# FM33FG0XXA register map
File version: 1.0
CPU: SC000 r1p0, little endian, MPU, no FPU, 3 interrupt priority bits
Registers are 32-bit, read-only, reset 0x0 unless marked. A register's access mark holds for its fields unless they carry their own. Offsets are from the block's base; [hi:lo] are bit positions; {n}, {i} and the like mark numbered series; 'fields as' and 'values as' point back to an identical list.

## CANFD0 — CANFD0 module information
Base 0x40020000
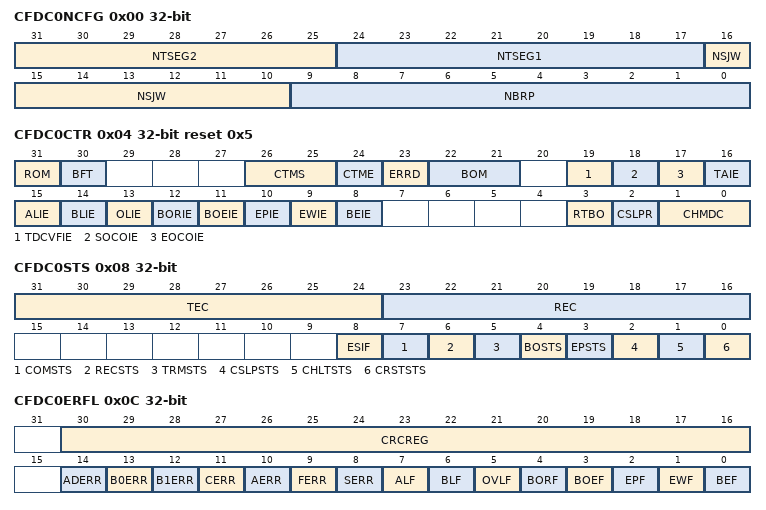
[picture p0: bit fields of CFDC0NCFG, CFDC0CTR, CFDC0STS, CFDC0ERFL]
0x00 CFDC0NCFG rw
  [31:25] NTSEG2 — NTSEG2 field description
  [24:17] NTSEG1 — NTSEG1 field description
  [16:10] NSJW — NSJW field description
  [9:0] NBRP — NBRP field description
0x04 CFDC0CTR rw reset 0x5
  [31] ROM — ROM field description
  [30] BFT — BFT field description
  [26:25] CTMS — CTMS field description
  [24] CTME — CTME field description
  [23] ERRD — ERRD field description
  [22:21] BOM — BOM field description
  [19] TDCVFIE — TDCVFIE field description
  [18] SOCOIE — SOCOIE field description
  [17] EOCOIE — EOCOIE field description
  [16] TAIE — TAIE field description
  [15] ALIE — ALIE field description
  [14] BLIE — BLIE field description
  [13] OLIE — OLIE field description
  [12] BORIE — BORIE field description
  [11] BOEIE — BOEIE field description
  [10] EPIE — EPIE field description
  [9] EWIE — EWIE field description
  [8] BEIE — BEIE field description
  [3] RTBO — RTBO field description
  [2] CSLPR — CSLPR field description
  [1:0] CHMDC — CHMDC field description
0x08 CFDC0STS access per field
  [31:24] TEC ro — TEC field description
  [23:16] REC ro — REC field description
  [8] ESIF rw — ESIF field description
  [7] COMSTS ro — COMSTS field description
  [6] RECSTS ro — RECSTS field description
  [5] TRMSTS ro — TRMSTS field description
  [4] BOSTS ro — BOSTS field description
  [3] EPSTS ro — EPSTS field description
  [2] CSLPSTS ro — CSLPSTS field description
  [1] CHLTSTS ro — CHLTSTS field description
  [0] CRSTSTS ro — CRSTSTS field description
0x0C CFDC0ERFL access per field
  [30:16] CRCREG ro — CRCREG field description
  [14] ADERR rw — ADERR field description
  [13] B0ERR rw — B0ERR field description
  [12] B1ERR rw — B1ERR field description
  [11] CERR rw — CERR field description
  [10] AERR rw — AERR field description
  [9] FERR rw — FERR field description
  [8] SERR rw — SERR field description
  [7] ALF rw — ALF field description
  [6] BLF rw — BLF field description
  [5] OVLF rw — OVLF field description
  [4] BORF rw — BORF field description
  [3] BOEF rw — BOEF field description
  [2] EPF rw — EPF field description
  [1] EWF rw — EWF field description
  [0] BEF rw — BEF field description
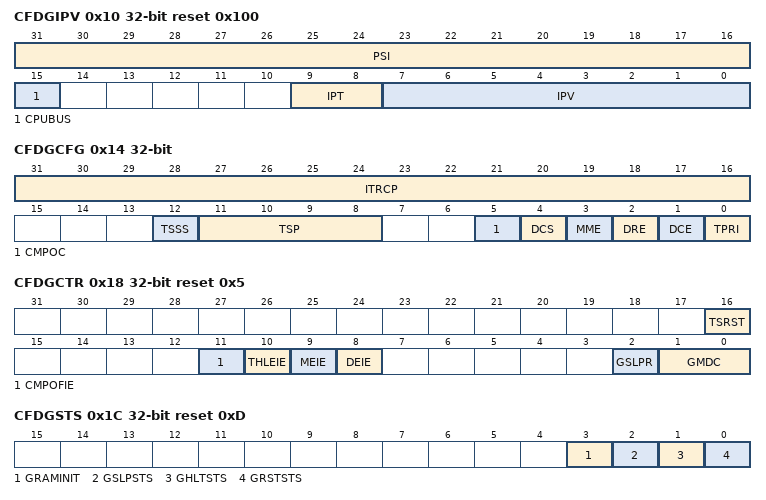
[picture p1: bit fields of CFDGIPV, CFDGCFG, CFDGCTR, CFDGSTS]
0x10 CFDGIPV reset 0x100
  [31:16] PSI — PSI field description
  [15] CPUBUS — CPUBUS field description
  [9:8] IPT — IPT field description
  [7:0] IPV — IPV field description
0x14 CFDGCFG rw
  [31:16] ITRCP — ITRCP field description
  [12] TSSS — TSSS field description
  [11:8] TSP — TSP field description
  [5] CMPOC — CMPOC field description
  [4] DCS — DCS field description
  [3] MME — MME field description
  [2] DRE — DRE field description
  [1] DCE — DCE field description
  [0] TPRI — TPRI field description
0x18 CFDGCTR rw reset 0x5
  [16] TSRST — TSRST field description
  [11] CMPOFIE — CMPOFIE field description
  [10] THLEIE — THLEIE field description
  [9] MEIE — MEIE field description
  [8] DEIE — DEIE field description
  [2] GSLPR — GSLPR field description
  [1:0] GMDC — GMDC field description
0x1C CFDGSTS reset 0xD
  [3] GRAMINIT — GRAMINIT field description
  [2] GSLPSTS — GSLPSTS field description
  [1] GHLTSTS — GHLTSTS field description
  [0] GRSTSTS — GRSTSTS field description
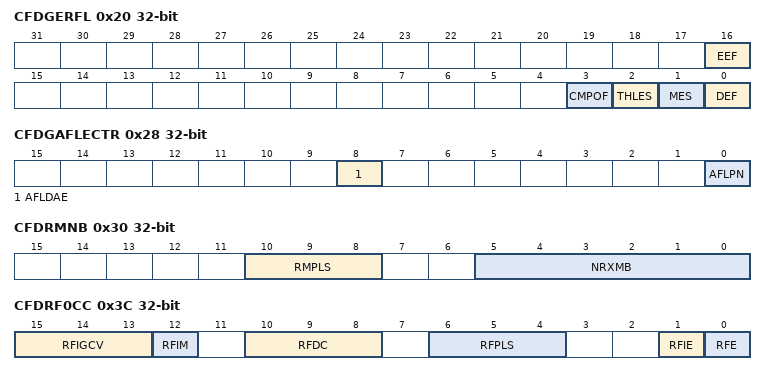
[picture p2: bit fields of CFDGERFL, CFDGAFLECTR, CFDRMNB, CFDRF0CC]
0x20 CFDGERFL access per field
  [16] EEF rw — EEF field description
  [3] CMPOF rw — CMPOF field description
  [2] THLES ro — THLES field description
  [1] MES ro — MES field description
  [0] DEF rw — DEF field description
0x24 CFDGTSC
  [15:0] TS — TS field description
0x28 CFDGAFLECTR rw
  [8] AFLDAE — AFLDAE field description
  [0] AFLPN — AFLPN field description
0x2C CFDGAFLCFG rw
  [21:16] RNC — RNC field description
0x30 CFDRMNB rw
  [10:8] RMPLS — RMPLS field description
  [5:0] NRXMB — NRXMB field description
0x34 CFDRMND rw
  [31:0] RMNSu — RMNSu field description
0x38 CFDRMIEC rw
  [31:0] RMIE — RMIE field description
0x3C CFDRF0CC rw
  [15:13] RFIGCV — RFIGCV field description
  [12] RFIM — RFIM field description
  [10:8] RFDC — RFDC field description
  [6:4] RFPLS — RFPLS field description
  [1] RFIE — RFIE field description
  [0] RFE — RFE field description
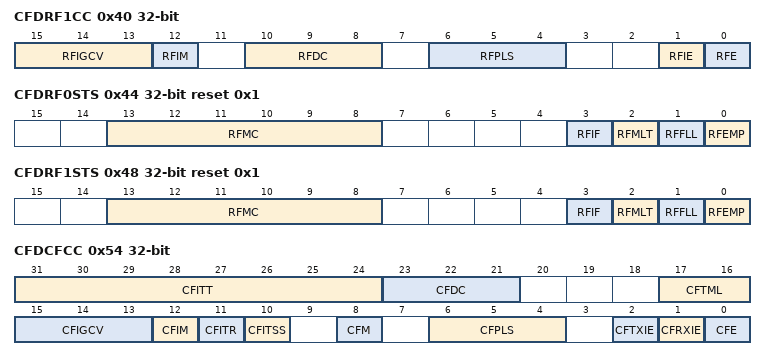
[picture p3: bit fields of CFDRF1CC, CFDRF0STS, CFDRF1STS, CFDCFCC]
0x40 CFDRF1CC rw
  fields as CFDRF0CC
0x44 CFDRF0STS access per field reset 0x1
  [13:8] RFMC ro — RFMC field description
  [3] RFIF rw — RFIF field description
  [2] RFMLT rw — RFMLT field description
  [1] RFFLL ro — RFFLL field description
  [0] RFEMP ro — RFEMP field description
0x48 CFDRF1STS access per field reset 0x1
  fields as CFDRF0STS
0x4C CFDRF0PCTR wo
  [7:0] RFPC — RFPC field description
0x50 CFDRF1PCTR wo
  [7:0] RFPC — RFPC field description
0x54 CFDCFCC rw
  [31:24] CFITT — CFITT field description
  [23:21] CFDC — CFDC field description
  [17:16] CFTML — CFTML field description
  [15:13] CFIGCV — CFIGCV field description
  [12] CFIM — CFIM field description
  [11] CFITR — CFITR field description
  [10] CFITSS — CFITSS field description
  [8] CFM — CFM field description
  [6:4] CFPLS — CFPLS field description
  [2] CFTXIE — CFTXIE field description
  [1] CFRXIE — CFRXIE field description
  [0] CFE — CFE field description
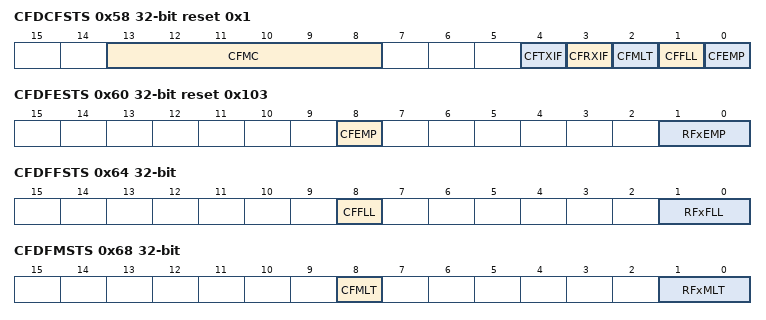
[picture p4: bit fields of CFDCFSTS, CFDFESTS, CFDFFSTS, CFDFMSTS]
0x58 CFDCFSTS access per field reset 0x1
  [13:8] CFMC ro — CFMC field description
  [4] CFTXIF rw — CFTXIF field description
  [3] CFRXIF rw — CFRXIF field description
  [2] CFMLT rw — CFMLT field description
  [1] CFFLL ro — CFFLL field description
  [0] CFEMP ro — CFEMP field description
0x5C CFDCFPCTR wo
  [7:0] CFPC — CFPC field description
0x60 CFDFESTS reset 0x103
  [8] CFEMP — CFEMP field description
  [1:0] RFxEMP — RFxEMP field description
0x64 CFDFFSTS
  [8] CFFLL — CFFLL field description
  [1:0] RFxFLL — RFxFLL field description
0x68 CFDFMSTS
  [8] CFMLT — CFMLT field description
  [1:0] RFxMLT — RFxMLT field description
0x6C CFDRFISTS
  [1:0] RFxIF — RFxIF field description
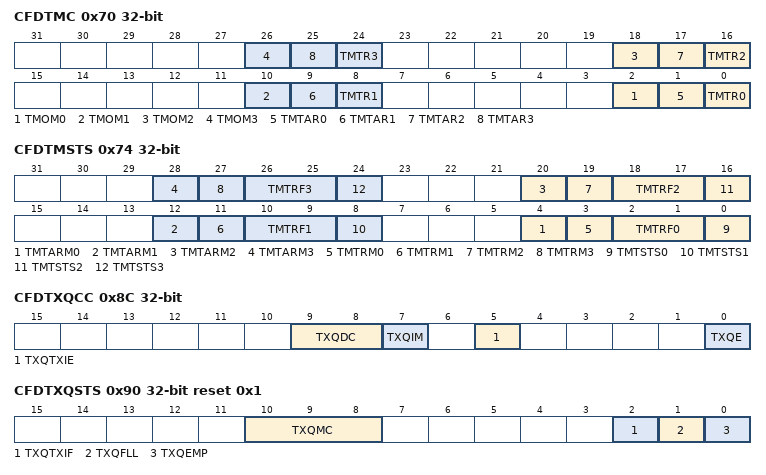
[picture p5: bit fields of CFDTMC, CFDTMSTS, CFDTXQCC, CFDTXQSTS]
0x70 CFDTMC rw
  [8n+2] TMOM{n} (n=0..3) — TMOM{n} field description
  [8n+1] TMTAR{n} (n=0..3) — TMTAR{n} field description
  [8n] TMTR{n} (n=0..3) — TMTR{n} field description
0x74 CFDTMSTS access per field
  [8n+4] TMTARM{n} ro (n=0..3) — TMTARM{n} field description
  [8n+3] TMTRM{n} ro (n=0..3) — TMTRM{n} field description
  [8n+2:8n+1] TMTRF{n} rw (n=0..3) — TMTRF{n} field description
  [8n] TMTSTS{n} ro (n=0..3) — TMTSTS{n} field description
0x78 CFDTMTRSTS
  [3:0] CFDTMTRSTS — CFDTMTRSTS field description
0x7C CFDTMTARSTS
  [3:0] CFDTMTARSTS — CFDTMTARSTS field description
0x80 CFDTMTCSTS
  [3:0] CFDTMTCSTS — CFDTMTCSTS field description
0x84 CFDTMTASTS
  [3:0] CFDTMTASTS — CFDTMTASTS field description
0x88 CFDTMIEC rw
  [3:0] TMIE — TMIE field description
0x8C CFDTXQCC rw
  [9:8] TXQDC — TXQDC field description
  [7] TXQIM — TXQIM field description
  [5] TXQTXIE — TXQTXIE field description
  [0] TXQE — TXQE field description
0x90 CFDTXQSTS access per field reset 0x1
  [10:8] TXQMC ro — TXQMC field description
  [2] TXQTXIF rw — TXQTXIF field description
  [1] TXQFLL ro — TXQFLL field description
  [0] TXQEMP ro — TXQEMP field description
0x94 CFDTXQPCTR wo
  [7:0] TXQPC — TXQPC field description
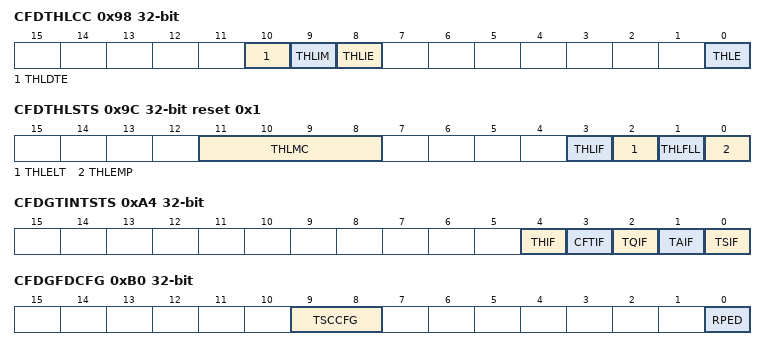
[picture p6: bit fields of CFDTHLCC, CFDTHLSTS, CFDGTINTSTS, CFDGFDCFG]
0x98 CFDTHLCC rw
  [10] THLDTE — THLDTE field description
  [9] THLIM — THLIM field description
  [8] THLIE — THLIE field description
  [0] THLE — THLE field description
0x9C CFDTHLSTS access per field reset 0x1
  [11:8] THLMC ro — THLMC field description
  [3] THLIF rw — THLIF field description
  [2] THLELT rw — THLELT field description
  [1] THLFLL ro — THLFLL field description
  [0] THLEMP ro — THLEMP field description
0xA0 CFDTHLPCTR wo
  [7:0] THLPC — THLPC field description
0xA4 CFDGTINTSTS
  [4] THIF — THIF field description
  [3] CFTIF — CFTIF field description
  [2] TQIF — TQIF field description
  [1] TAIF — TAIF field description
  [0] TSIF — TSIF field description
0xA8 CFDGTSTCFG rw
  [19:16] RTMPS — RTMPS field description
0xAC CFDGTSTCTR rw
  [2] RTME — RTME field description
0xB0 CFDGFDCFG rw
  [9:8] TSCCFG — TSCCFG field description
  [0] RPED — RPED field description
0xB8 CFDGLOCKK wo
  [15:0] LOCK — LOCK field description
0xC0 CFDGAFLIGNENT rw
  [4:0] IRN — IRN field description
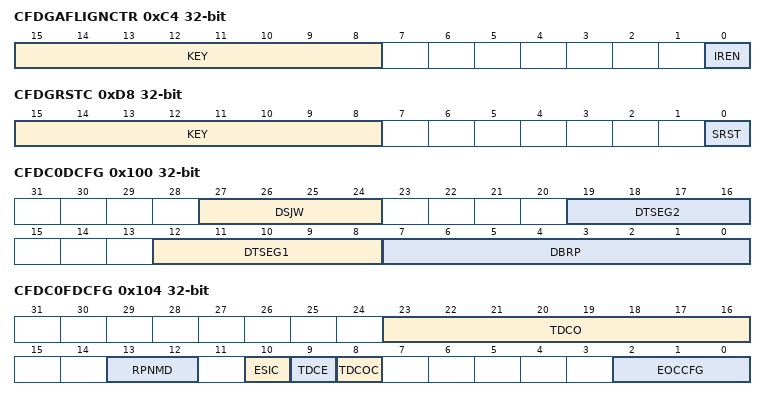
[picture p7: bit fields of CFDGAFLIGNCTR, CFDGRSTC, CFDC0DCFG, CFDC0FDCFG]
0xC4 CFDGAFLIGNCTR rw
  [15:8] KEY — KEY field description
  [0] IREN — IREN field description
0xD0 CFDGPFLECTR rw
  [8] PFLDAE — PFLDAE field description
0xD4 CFDGPFLCFG rw
  [25:24] RNC — RNC field description
0xD8 CFDGRSTC rw
  [15:8] KEY — KEY field description
  [0] SRST — SRST field description
0x100 CFDC0DCFG rw
  [27:24] DSJW — DSJW field description
  [19:16] DTSEG2 — DTSEG2 field description
  [12:8] DTSEG1 — DTSEG1 field description
  [7:0] DBRP — DBRP field description
0x104 CFDC0FDCFG rw
  [23:16] TDCO — TDCO field description
  [13:12] RPNMD — RPNMD field description
  [10] ESIC — ESIC field description
  [9] TDCE — TDCE field description
  [8] TDCOC — TDCOC field description
  [2:0] EOCCFG — EOCCFG field description
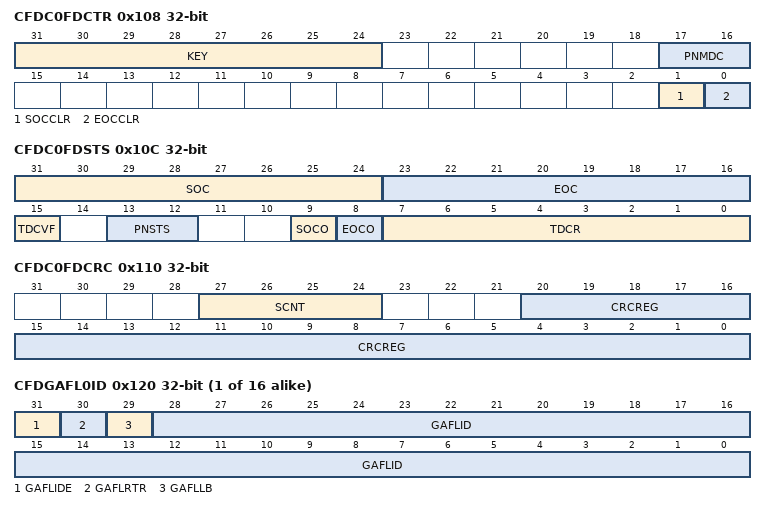
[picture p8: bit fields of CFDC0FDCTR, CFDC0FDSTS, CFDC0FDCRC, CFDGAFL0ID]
0x108 CFDC0FDCTR rw
  [31:24] KEY — KEY field description
  [17:16] PNMDC — PNMDC field description
  [1] SOCCLR — SOCCLR field description
  [0] EOCCLR — EOCCLR field description
0x10C CFDC0FDSTS access per field
  [31:24] SOC ro — SOC field description
  [23:16] EOC ro — EOC field description
  [15] TDCVF rw — TDCVF field description
  [13:12] PNSTS ro — PNSTS field description
  [9] SOCO rw — SOCO field description
  [8] EOCO rw — EOCO field description
  [7:0] TDCR ro — TDCR field description
0x110 CFDC0FDCRC
  [27:24] SCNT — SCNT field description
  [20:0] CRCREG — CRCREG field description
{0x120+0x10*i} CFDGAFL{i}ID rw (i=0..15)
  [31] GAFLIDE — GAFLIDE field description
  [30] GAFLRTR — GAFLRTR field description
  [29] GAFLLB — GAFLLB field description
  [28:0] GAFLID — GAFLID field description
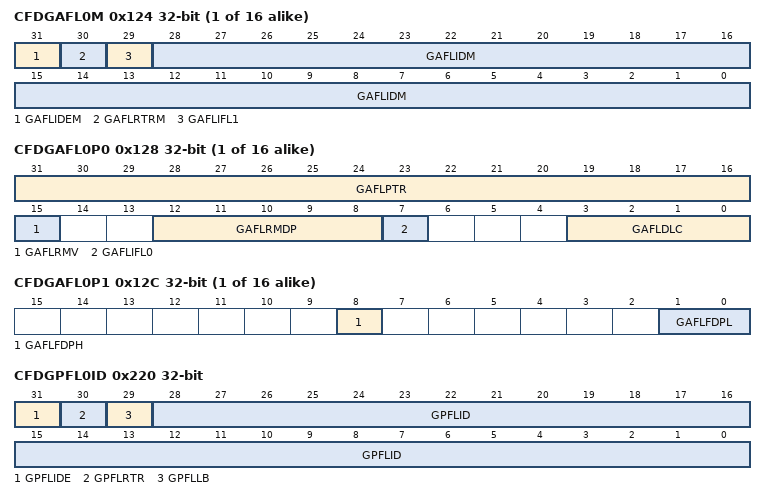
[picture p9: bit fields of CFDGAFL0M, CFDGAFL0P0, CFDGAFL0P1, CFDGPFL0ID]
{0x124+0x10*i} CFDGAFL{i}M rw (i=0..15)
  [31] GAFLIDEM — GAFLIDEM field description
  [30] GAFLRTRM — GAFLRTRM field description
  [29] GAFLIFL1 — GAFLIFL1 field description
  [28:0] GAFLIDM — GAFLIDM field description
{0x128+0x10*i} CFDGAFL{i}P0 rw (i=0..15)
  [31:16] GAFLPTR — GAFLPTR field description
  [15] GAFLRMV — GAFLRMV field description
  [12:8] GAFLRMDP — GAFLRMDP field description
  [7] GAFLIFL0 — GAFLIFL0 field description
  [3:0] GAFLDLC — GAFLDLC field description
{0x12C+0x10*i} CFDGAFL{i}P1 rw (i=0..15)
  [8] GAFLFDPH — GAFLFDPH field description
  [1:0] GAFLFDPL — GAFLFDPL field description
0x220 CFDGPFL0ID rw
  [31] GPFLIDE — GPFLIDE field description
  [30] GPFLRTR — GPFLRTR field description
  [29] GPFLLB — GPFLLB field description
  [28:0] GPFLID — GPFLID field description
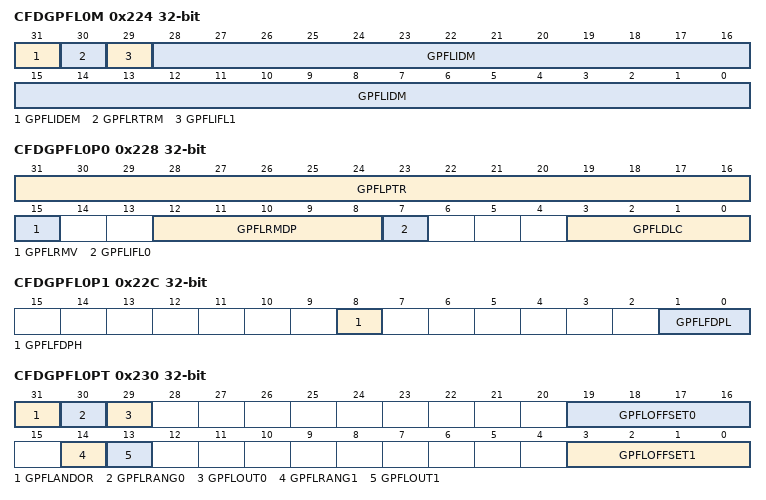
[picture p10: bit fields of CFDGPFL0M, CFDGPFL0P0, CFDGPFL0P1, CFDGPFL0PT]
0x224 CFDGPFL0M rw
  [31] GPFLIDEM — GPFLIDEM field description
  [30] GPFLRTRM — GPFLRTRM field description
  [29] GPFLIFL1 — GPFLIFL1 field description
  [28:0] GPFLIDM — GPFLIDM field description
0x228 CFDGPFL0P0 rw
  [31:16] GPFLPTR — GPFLPTR field description
  [15] GPFLRMV — GPFLRMV field description
  [12:8] GPFLRMDP — GPFLRMDP field description
  [7] GPFLIFL0 — GPFLIFL0 field description
  [3:0] GPFLDLC — GPFLDLC field description
0x22C CFDGPFL0P1 rw
  [8] GPFLFDPH — GPFLFDPH field description
  [1:0] GPFLFDPL — GPFLFDPL field description
0x230 CFDGPFL0PT rw
  [31] GPFLANDOR — GPFLANDOR field description
  [30] GPFLRANG0 — GPFLRANG0 field description
  [29] GPFLOUT0 — GPFLOUT0 field description
  [19:16] GPFLOFFSET0 — GPFLOFFSET0 field description
  [14] GPFLRANG1 — GPFLRANG1 field description
  [13] GPFLOUT1 — GPFLOUT1 field description
  [3:0] GPFLOFFSET1 — GPFLOFFSET1 field description
0x234 CFDGPFL0PD0 rw
  [31:0] FDATA — FDATA field description
0x238 CFDGPFL0PM0 rw
  [31:0] FMASK — FMASK field description
0x23C CFDGPFL0PD1 rw
  [31:0] FDATA — FDATA field description
0x240 CFDGPFL0PM1 rw
  [31:0] FMASK — FMASK field description
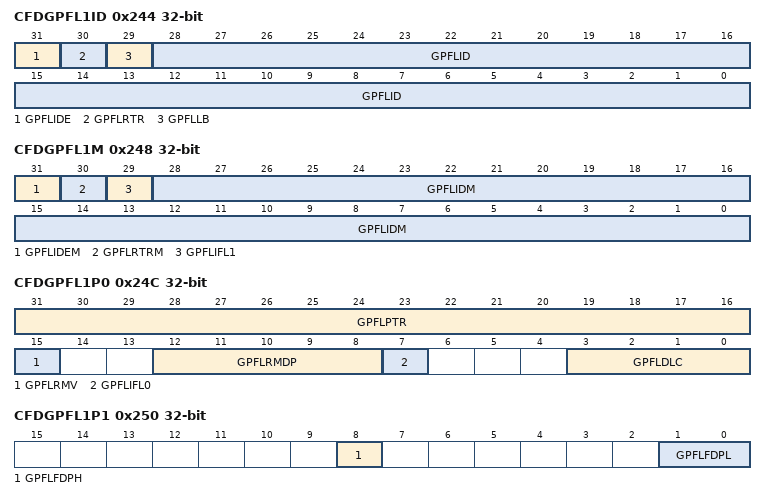
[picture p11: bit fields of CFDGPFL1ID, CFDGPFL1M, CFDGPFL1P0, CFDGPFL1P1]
0x244 CFDGPFL1ID rw
  fields as CFDGPFL0ID
0x248 CFDGPFL1M rw
  fields as CFDGPFL0M
0x24C CFDGPFL1P0 rw
  fields as CFDGPFL0P0
0x250 CFDGPFL1P1 rw
  fields as CFDGPFL0P1
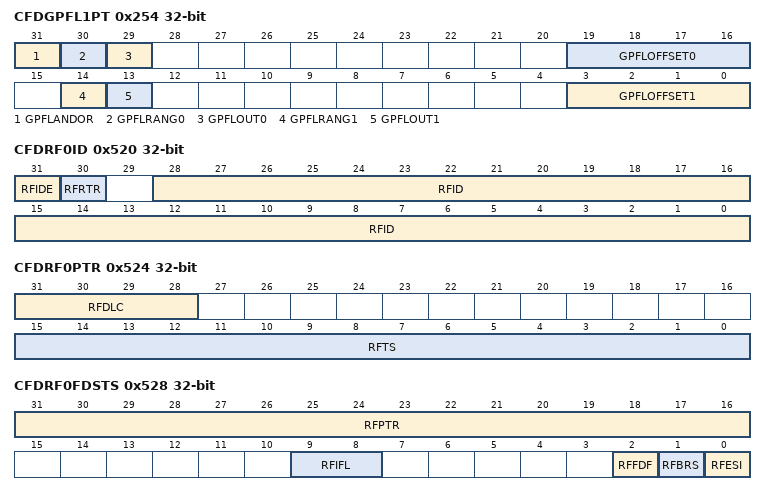
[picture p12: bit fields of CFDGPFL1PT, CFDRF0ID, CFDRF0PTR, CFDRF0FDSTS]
0x254 CFDGPFL1PT rw
  fields as CFDGPFL0PT
0x258 CFDGPFL1PD0 rw
  [31:0] FDATA — FDATA field description
0x25C CFDGPFL1PM0 rw
  [31:0] FMASK — FMASK field description
0x260 CFDGPFL1PD1 rw
  [31:0] FDATA — FDATA field description
0x264 CFDGPFL1PM1 rw
  [31:0] FMASK — FMASK field description
{0x280+4i} CFDRPGACC{i} rw (i=0..63)
  [31:0] RDTA — RDTA field description
0x520 CFDRF0ID
  [31] RFIDE — RFIDE field description
  [30] RFRTR — RFRTR field description
  [28:0] RFID — RFID field description
0x524 CFDRF0PTR
  [31:28] RFDLC — RFDLC field description
  [15:0] RFTS — RFTS field description
0x528 CFDRF0FDSTS
  [31:16] RFPTR — RFPTR field description
  [9:8] RFIFL — RFIFL field description
  [2] RFFDF — RFFDF field description
  [1] RFBRS — RFBRS field description
  [0] RFESI — RFESI field description
{0x52C+4i} CFDRF0DF{i} (i=0..15)
  [31:0] RFDB — RFDB field description
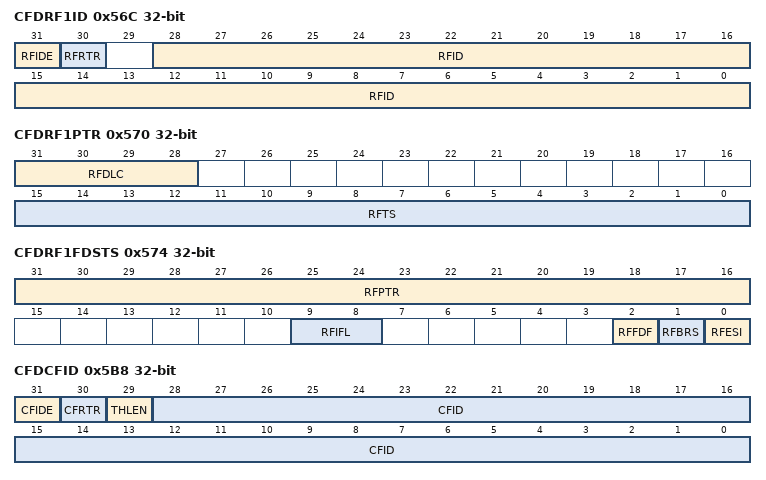
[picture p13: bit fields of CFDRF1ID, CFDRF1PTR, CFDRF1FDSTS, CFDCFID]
0x56C CFDRF1ID
  fields as CFDRF0ID
0x570 CFDRF1PTR
  fields as CFDRF0PTR
0x574 CFDRF1FDSTS
  fields as CFDRF0FDSTS
{0x578+4i} CFDRF1DF{i} (i=0..15)
  [31:0] RFDB — RFDB field description
0x5B8 CFDCFID rw
  [31] CFIDE — CFIDE field description
  [30] CFRTR — CFRTR field description
  [29] THLEN — THLEN field description
  [28:0] CFID — CFID field description
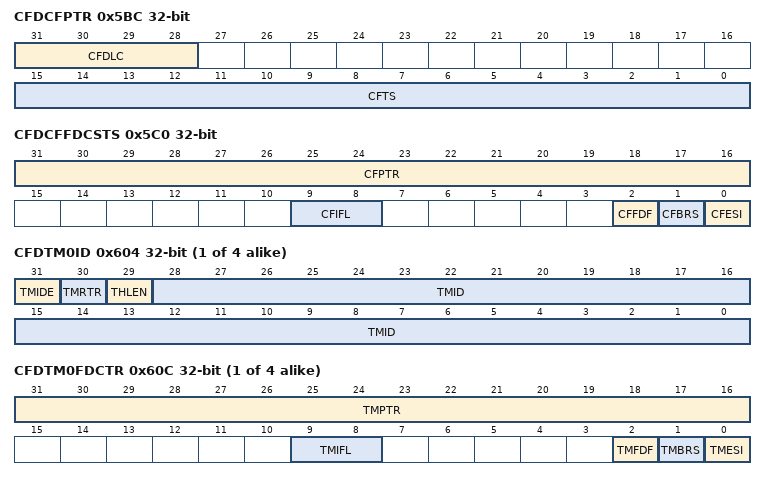
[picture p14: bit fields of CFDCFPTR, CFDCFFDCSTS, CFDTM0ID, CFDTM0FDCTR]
0x5BC CFDCFPTR rw
  [31:28] CFDLC — CFDLC field description
  [15:0] CFTS — CFTS field description
0x5C0 CFDCFFDCSTS rw
  [31:16] CFPTR — CFPTR field description
  [9:8] CFIFL — CFIFL field description
  [2] CFFDF — CFFDF field description
  [1] CFBRS — CFBRS field description
  [0] CFESI — CFESI field description
{0x5C4+4i} CFDCFDF{i} rw (i=0..15)
  [31:0] CFDB — CFDB field description
{0x604+0x4C*i} CFDTM{i}ID rw (i=0..3)
  [31] TMIDE — TMIDE field description
  [30] TMRTR — TMRTR field description
  [29] THLEN — THLEN field description
  [28:0] TMID — TMID field description
{0x608+0x4C*i} CFDTM{i}PTR rw (i=0..3)
  [31:28] TMDLC — TMDLC field description
{0x60C+0x4C*i} CFDTM{i}FDCTR rw (i=0..3)
  [31:16] TMPTR — TMPTR field description
  [9:8] TMIFL — TMIFL field description
  [2] TMFDF — TMFDF field description
  [1] TMBRS — TMBRS field description
  [0] TMESI — TMESI field description
{0x610+4i} CFDTM0DF{i} rw (i=0..15)
  [31:0] TMDB — TMDB field description
{0x65C+4i} CFDTM1DF{i} rw (i=0..15)
  [31:0] TMDB — TMDB field description
{0x6A8+4i} CFDTM2DF{i} rw (i=0..15)
  [31:0] TMDB — TMDB field description
{0x6F4+4i} CFDTM3DF{i} rw (i=0..15)
  [31:0] TMDB — TMDB field description
0x740 CFDTHLACC0
  [31:16] TMTS — TMTS field description
  [4:3] BN — BN field description
  [2:0] BT — BT field description
0x744 CFDTHLACC1
  [17:16] TIFL — TIFL field description
  [15:0] TID — TID field description
{0x920+0x4C*i} CFDRM{i}ID (i=0..7)
  [31] RMIDE — RMIDE field description
  [30] RMRTR — RMRTR field description
  [28:0] RMID — RMID field description
{0x924+0x4C*i} CFDRM{i}PTR (i=0..7)
  [31:28] RMDLC — RMDLC field description
  [15:0] RMTS — RMTS field description
{0x928+0x4C*i} CFDRM{i}FDSTS (i=0..7)
  [31:16] RMPTR — RMPTR field description
  [9:8] RMIFL — RMIFL field description
  [2] RMFDF — RMFDF field description
  [1] RMBRS — RMBRS field description
  [0] RMESI — RMESI field description
{0x92C+4i} CFDRM0DF{i} (i=0..15)
  [31:0] RMDB — RMDB field description
{0x978+4i} CFDRM1DF{i} (i=0..15)
  [31:0] RMDB — RMDB field description
{0x9C4+4i} CFDRM2DF{i} (i=0..15)
  [31:0] RMDB — RMDB field description
{0xA10+4i} CFDRM3DF{i} (i=0..15)
  [31:0] RMDB — RMDB field description
{0xA5C+4i} CFDRM4DF{i} (i=0..15)
  [31:0] RMDB — RMDB field description
{0xAA8+4i} CFDRM5DF{i} (i=0..15)
  [31:0] RMDB — RMDB field description
{0xAF4+4i} CFDRM6DF{i} (i=0..15)
  [31:0] RMDB — RMDB field description
{0xB40+4i} CFDRM7DF{i} (i=0..15)
  [31:0] RMDB — RMDB field description
{0xAC0+0x4C*i} CFDRM{i}ID (i=8..15)
  fields as CFDRM0ID
{0xAC4+0x4C*i} CFDRM{i}PTR (i=8..15)
  fields as CFDRM0PTR
{0xAC8+0x4C*i} CFDRM{i}FDSTS (i=8..15)
  fields as CFDRM0FDSTS
{0xD2C+4i} CFDRM8DF{i} (i=0..15)
  [31:0] RMDB — RMDB field description
{0xD78+4i} CFDRM9DF{i} (i=0..15)
  [31:0] RMDB — RMDB field description
{0xDC4+4i} CFDRM10DF{i} (i=0..15)
  [31:0] RMDB — RMDB field description
{0xE10+4i} CFDRM11DF{i} (i=0..15)
  [31:0] RMDB — RMDB field description
{0xE5C+4i} CFDRM12DF{i} (i=0..15)
  [31:0] RMDB — RMDB field description
{0xEA8+4i} CFDRM13DF{i} (i=0..15)
  [31:0] RMDB — RMDB field description
{0xEF4+4i} CFDRM14DF{i} (i=0..15)
  [31:0] RMDB — RMDB field description
{0xF40+4i} CFDRM15DF{i} (i=0..15)
  [31:0] RMDB — RMDB field description
{0xC60+0x4C*i} CFDRM{i}ID (i=16..23)
  fields as CFDRM0ID
{0xC64+0x4C*i} CFDRM{i}PTR (i=16..23)
  fields as CFDRM0PTR
{0xC68+0x4C*i} CFDRM{i}FDSTS (i=16..23)
  fields as CFDRM0FDSTS
{0x112C+4i} CFDRM16DF{i} (i=0..15)
  [31:0] RMDB — RMDB field description
{0x1178+4i} CFDRM17DF{i} (i=0..15)
  [31:0] RMDB — RMDB field description
{0x11C4+4i} CFDRM18DF{i} (i=0..15)
  [31:0] RMDB — RMDB field description
{0x1210+4i} CFDRM19DF{i} (i=0..15)
  [31:0] RMDB — RMDB field description
{0x125C+4i} CFDRM20DF{i} (i=0..15)
  [31:0] RMDB — RMDB field description
{0x12A8+4i} CFDRM21DF{i} (i=0..15)
  [31:0] RMDB — RMDB field description
{0x12F4+4i} CFDRM22DF{i} (i=0..15)
  [31:0] RMDB — RMDB field description
{0x1340+4i} CFDRM23DF{i} (i=0..15)
  [31:0] RMDB — RMDB field description
{0xE00+0x4C*i} CFDRM{i}ID (i=24..31)
  fields as CFDRM0ID
{0xE04+0x4C*i} CFDRM{i}PTR (i=24..31)
  fields as CFDRM0PTR
{0xE08+0x4C*i} CFDRM{i}FDSTS (i=24..31)
  fields as CFDRM0FDSTS
{0x152C+4i} CFDRM24DF{i} (i=0..15)
  [31:0] RMDB — RMDB field description
{0x1578+4i} CFDRM25DF{i} (i=0..15)
  [31:0] RMDB — RMDB field description
{0x15C4+4i} CFDRM26DF{i} (i=0..15)
  [31:0] RMDB — RMDB field description
{0x1610+4i} CFDRM27DF{i} (i=0..15)
  [31:0] RMDB — RMDB field description
{0x165C+4i} CFDRM28DF{i} (i=0..15)
  [31:0] RMDB — RMDB field description
{0x16A8+4i} CFDRM29DF{i} (i=0..15)
  [31:0] RMDB — RMDB field description
{0x16F4+4i} CFDRM30DF{i} (i=0..15)
  [31:0] RMDB — RMDB field description
{0x1740+4i} CFDRM31DF{i} (i=0..15)
  [31:0] RMDB — RMDB field description

## CANFD1 — CANFD1 module information
Base 0x40024000
Registers as CANFD0, without CFDTM2PTR, CFDTM3PTR; these are added or differ:
0x44 CFDRF0STS access per field
  fields as CANFD0.CFDRF0STS
0x48 CFDRF1STS access per field
  fields as CANFD0.CFDRF0STS
